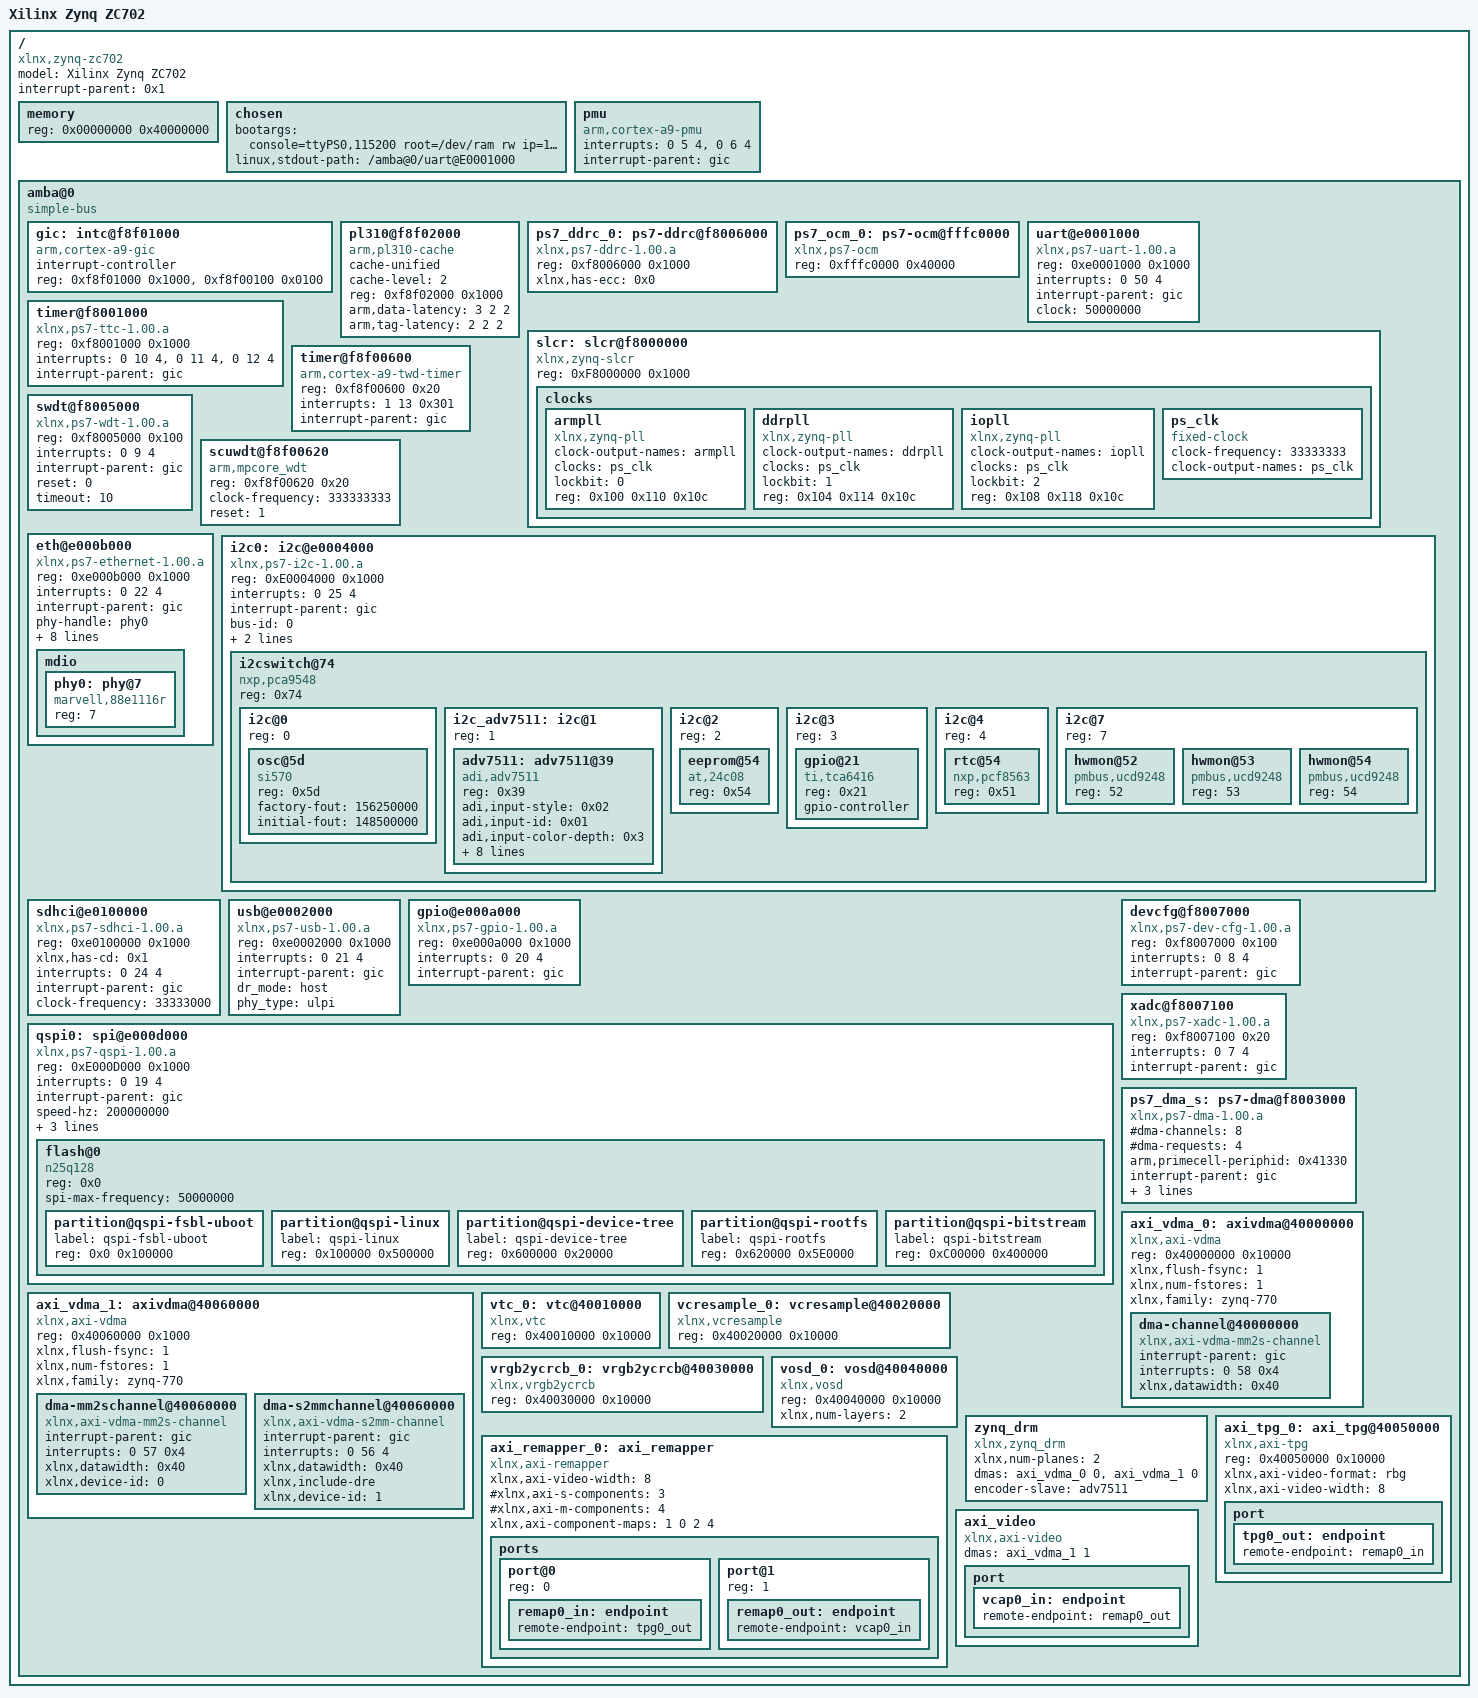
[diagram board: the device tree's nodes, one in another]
/dts-v1/;

/ {
	model = "Xilinx Zynq ZC702";
	compatible = "xlnx,zynq-zc702";
	#address-cells = <0x1>;
	#size-cells = <0x1>;
	interrupt-parent = <0x1>;

	memory {
		device_type = "memory";
		reg = <0x00000000 0x40000000>;
	};
	chosen {
		bootargs = "console=ttyPS0,115200 root=/dev/ram rw ip=192.168.1.10:::255.255.255.0:ZC702:eth0 earlyprintk";
		linux,stdout-path = "/amba@0/uart@E0001000";
	};

	pmu {
		compatible = "arm,cortex-a9-pmu";
		interrupts = <0 5 4>, <0 6 4>;
		interrupt-parent = <&gic>;
	};

	amba@0 {
		compatible = "simple-bus";
		#address-cells = <0x1>;
		#size-cells = <0x1>;
		ranges;

		gic: intc@f8f01000 {
			interrupt-controller;
			compatible = "arm,cortex-a9-gic";
			#interrupt-cells = <3>;
			reg = <0xf8f01000 0x1000>,
			      <0xf8f00100 0x0100>;
		};

		pl310@f8f02000 {
			compatible = "arm,pl310-cache";
			cache-unified;
			cache-level = <2>;
			reg = <0xf8f02000 0x1000>;
			arm,data-latency = <3 2 2>;
			arm,tag-latency = <2 2 2>;
		};

		ps7_ddrc_0: ps7-ddrc@f8006000 {
			compatible = "xlnx,ps7-ddrc-1.00.a", "xlnx,ps7-ddrc";
			reg = <0xf8006000 0x1000>;
			xlnx,has-ecc = <0x0>;
		} ;

		ps7_ocm_0: ps7-ocm@fffc0000 {
			compatible = "xlnx,ps7-ocm";
			reg = <0xfffc0000 0x40000>; /* 256k */
		};

		uart@e0001000 {
			compatible = "xlnx,ps7-uart-1.00.a";
			reg = <0xe0001000 0x1000>;
			interrupts = <0 50 4>;
			interrupt-parent = <&gic>;
			clock = <50000000>;
		};

		slcr: slcr@f8000000 {
			compatible = "xlnx,zynq-slcr";
			reg = <0xF8000000 0x1000>;
			clocks {
				#address-cells = <1>;
				#size-cells = <0>;
				armpll: armpll {
					#clock-cells = <0>;
					clock-output-names = "armpll";
					clocks = <&ps_clk>;
					compatible = "xlnx,zynq-pll";
					lockbit = <0>;
					reg = < 0x100 0x110 0x10c >;
				} ;
				ddrpll: ddrpll {
					#clock-cells = <0>;
					clock-output-names = "ddrpll";
					clocks = <&ps_clk>;
					compatible = "xlnx,zynq-pll";
					lockbit = <1>;
					reg = < 0x104 0x114 0x10c >;
				} ;
				iopll: iopll {
					#clock-cells = <0>;
					clock-output-names = "iopll";
					clocks = <&ps_clk>;
					compatible = "xlnx,zynq-pll";
					lockbit = <2>;
					reg = < 0x108 0x118 0x10c >;
				} ;
				ps_clk: ps_clk {
					#clock-cells = <0>;
					clock-frequency = <33333333>;
					clock-output-names = "ps_clk";
					compatible = "fixed-clock";
				} ;
			} ;
		};

		timer@f8001000 {
			compatible = "xlnx,ps7-ttc-1.00.a";
			reg = <0xf8001000 0x1000>;
			interrupts = <0 10 4>,<0 11 4>,<0 12 4>;
			interrupt-parent = <&gic>;
		};

		timer@f8f00600 {
			compatible = "arm,cortex-a9-twd-timer";
			reg = <0xf8f00600 0x20>;
			interrupts = <1 13 0x301>;
			interrupt-parent = <&gic>;
		};

		swdt@f8005000 {
			device_type = "watchdog";
			compatible = "xlnx,ps7-wdt-1.00.a";
			reg = <0xf8005000 0x100>;
			interrupts = <0 9 4>;
			interrupt-parent = <&gic>;
			reset = <0>;
			timeout = <10>;
		};

		scuwdt@f8f00620 {
			device_type = "watchdog";
			compatible = "arm,mpcore_wdt";
			reg = <0xf8f00620 0x20>;
			clock-frequency = <333333333>;
			reset = <1>;
		};

		eth@e000b000 {
			compatible = "xlnx,ps7-ethernet-1.00.a";
			reg = <0xe000b000 0x1000>;
			interrupts = <0 22 4>;
			interrupt-parent = <&gic>;
			phy-handle = <&phy0>;
			phy-mode = "rgmii-id";
			xlnx,ptp-enet-clock = <111111111>;
			xlnx,slcr-div0-1000Mbps = <8>;
			xlnx,slcr-div0-100Mbps = <8>;
			xlnx,slcr-div0-10Mbps = <8>;
			xlnx,slcr-div1-1000Mbps = <1>;
			xlnx,slcr-div1-100Mbps = <5>;
			xlnx,slcr-div1-10Mbps = <50>;
			#address-cells = <0x1>;
			#size-cells = <0x0>;
			mdio {
				#address-cells = <1>;
				#size-cells = <0>;
				phy0: phy@7 {
					compatible = "marvell,88e1116r";
					device_type = "ethernet-phy";
					reg = <7>;
				};
			};
		};

		i2c0: i2c@e0004000 {
			compatible = "xlnx,ps7-i2c-1.00.a";
			reg = <0xE0004000 0x1000>;
			interrupts = <0 25 4>;
			interrupt-parent = <&gic>;
			bus-id = <0>;
			input-clk = <111111111>;
			i2c-clk = <100000>;

			#address-cells = <1>;
			#size-cells = <0>;
			i2cswitch@74 {
				compatible = "nxp,pca9548";
				#address-cells = <1>;
				#size-cells = <0>;
				reg = <0x74>;

				i2c@0 {
					#address-cells = <1>;
					#size-cells = <0>;
					reg = <0>;
					osc@5d {
						compatible = "si570";
						reg = <0x5d>;
						factory-fout = <156250000>;
						initial-fout = <148500000>;
					};
				};

				i2c_adv7511: i2c@1 {
					#size-cells = <0>;
					#address-cells = <1>;
					reg = <1>;
					adv7511: adv7511@39 {
						compatible = "adi,adv7511";
						reg = <0x39>;
						adi,input-style = <0x02>;
						adi,input-id = <0x01>;
						adi,input-color-depth = <0x3>;
						adi,sync-pulse = <0x03>;
						adi,bit-justification = <0x01>;
						adi,up-conversion = <0x00>;
						adi,timing-generation-sequence = <0x00>;
						adi,vsync-polarity = <0x02>;
						adi,hsync-polarity = <0x02>;
						adi,tdms-clock-inversion;
						adi,clock-delay = <0x03>;
					};
				};

				i2c@2 {
					#address-cells = <1>;
					#size-cells = <0>;
					reg = <2>;
					eeprom@54 {
						compatible = "at,24c08";
						reg = <0x54>;
					};
				};

				i2c@3 {
					#address-cells = <1>;
					#size-cells = <0>;
					reg = <3>;
					gpio@21 {
						compatible = "ti,tca6416";
						reg = <0x21>;
						gpio-controller;
						#gpio-cells = <2>;
					};
				};

				i2c@4 {
					#address-cells = <1>;
					#size-cells = <0>;
					reg = <4>;
					rtc@54 {
						compatible = "nxp,pcf8563";
						reg = <0x51>;
					};
				};

				i2c@7 {
					#address-cells = <1>;
					#size-cells = <0>;
					reg = <7>;
					hwmon@52 {
						compatible = "pmbus,ucd9248";
						reg = <52>;
					};
					hwmon@53 {
						compatible = "pmbus,ucd9248";
						reg = <53>;
					};
					hwmon@54 {
						compatible = "pmbus,ucd9248";
						reg = <54>;
					};
				};
			};
		};

		sdhci@e0100000 {
			compatible = "xlnx,ps7-sdhci-1.00.a";
			reg = <0xe0100000 0x1000>;
			xlnx,has-cd = <0x1>;
			interrupts = <0 24 4>;
			interrupt-parent = <&gic>;
			clock-frequency = <33333000>;
		};

		usb@e0002000 {
			compatible = "xlnx,ps7-usb-1.00.a";
			reg = <0xe0002000 0x1000>;
			interrupts = <0 21 4>;
			interrupt-parent = <&gic>;
			dr_mode = "host";
			phy_type = "ulpi";
		};

		gpio@e000a000 {
			compatible = "xlnx,ps7-gpio-1.00.a";
			reg = <0xe000a000 0x1000>;
			interrupts = <0 20 4>;
			interrupt-parent = <&gic>;
		};

		qspi0: spi@e000d000 {
			compatible = "xlnx,ps7-qspi-1.00.a";
			reg = <0xE000D000 0x1000>;
			interrupts = <0 19 4>;
			interrupt-parent = <&gic>;
			speed-hz = <200000000>;
			bus-num = <1>;
			num-chip-select = <1>;
			#address-cells = <1>;
			#size-cells = <0>;
			is-dual = <0>;
			flash@0 {
				compatible = "n25q128";
				reg = <0x0>;
				spi-max-frequency = <50000000>;
				#address-cells = <1>;
				#size-cells = <1>;
				partition@qspi-fsbl-uboot {
					label = "qspi-fsbl-uboot";
					reg = <0x0 0x100000>;
				};
				partition@qspi-linux {
					label = "qspi-linux";
					reg = <0x100000 0x500000>;
				};
				partition@qspi-device-tree {
					label = "qspi-device-tree";
					reg = <0x600000 0x20000>;
				};
				partition@qspi-rootfs {
					label = "qspi-rootfs";
					reg = <0x620000 0x5E0000>;
				};
				partition@qspi-bitstream {
					label = "qspi-bitstream";
					reg = <0xC00000 0x400000>;
				};
			};
		};

		devcfg@f8007000 {
			compatible = "xlnx,ps7-dev-cfg-1.00.a";
			reg = <0xf8007000 0x100>;
			interrupts = <0 8 4>;
			interrupt-parent = <&gic>;
		};

		xadc@f8007100 {
			compatible = "xlnx,ps7-xadc-1.00.a";
			reg = <0xf8007100 0x20>;
			interrupts = <0 7 4>;
			interrupt-parent = <&gic>;
		};

		ps7_dma_s: ps7-dma@f8003000 {
			#dma-cells = <1>;
			#dma-channels = <8>;
			#dma-requests = <4>;
			arm,primecell-periphid = <0x41330>;
			compatible = "xlnx,ps7-dma-1.00.a", "arm,primecell", "arm,pl330";
			interrupt-parent = <&gic>;
			interrupts = <0 13 4 0 14 4 0 15 4 0 16 4 0 17 4 0 40 4 0 41 4 0 42 4 0 43 4>;
			reg = <0xf8003000 0x1000>;
		};

		axi_vdma_0: axivdma@40000000 {
			compatible = "xlnx,axi-vdma";
			reg = <0x40000000 0x10000>;

			xlnx,flush-fsync = <1>;
			xlnx,num-fstores = <1>;
			xlnx,family = "zynq-770";

			#dma-cells = <1>;
			dma-channel@40000000 {
				compatible = "xlnx,axi-vdma-mm2s-channel";
				interrupt-parent = <&gic>;
				interrupts = <0 58 0x4>;
				xlnx,datawidth = <0x40>;
			};
		};

		axi_vdma_1: axivdma@40060000 {
			compatible = "xlnx,axi-vdma";
			reg = <0x40060000 0x1000>;

			xlnx,flush-fsync = <1>;
			xlnx,num-fstores = <1>;
			xlnx,family = "zynq-770";

			#dma-cells = <1>;
			dma-mm2schannel@40060000 {
				compatible = "xlnx,axi-vdma-mm2s-channel";
				interrupt-parent = <&gic>;
				interrupts = <0 57 0x4>;
				xlnx,datawidth = <0x40>;
				xlnx,device-id = <0>;
			};
			dma-s2mmchannel@40060000 {
				compatible = "xlnx,axi-vdma-s2mm-channel";
				interrupt-parent = <&gic>;
				interrupts = <0 56 4>;
				xlnx,datawidth = <0x40>;
				xlnx,include-dre;
				xlnx,device-id = <1>;
			};
		};

		vtc_0: vtc@40010000 {
			compatible = "xlnx,vtc";
			reg = <0x40010000 0x10000>;
		};

		vcresample_0: vcresample@40020000 {
			compatible = "xlnx,vcresample";
			reg = <0x40020000 0x10000>;
		};

		vrgb2ycrcb_0: vrgb2ycrcb@40030000 {
			compatible = "xlnx,vrgb2ycrcb";
			reg = <0x40030000 0x10000>;
		};

		vosd_0: vosd@40040000 {
			compatible = "xlnx,vosd";
			reg = <0x40040000 0x10000>;
			xlnx,num-layers = <2>;
		};

		zynq_drm{
			compatible = "xlnx,zynq_drm";
			xlnx,num-planes = <2>;
			dmas = <&axi_vdma_0 0
				&axi_vdma_1 0>;
			dma-names = "vdma0", "vdma1";
			encoder-slave = <&adv7511>;
		};

		axi_tpg_0: axi_tpg@40050000 {
			compatible = "xlnx,axi-tpg";
			reg = <0x40050000 0x10000>;

			xlnx,axi-video-format = "rbg";
			xlnx,axi-video-width = <8>;

			port {
				tpg0_out: endpoint {
					remote-endpoint = <&remap0_in>;
				};
			};
		};

		axi_remapper_0: axi_remapper {
			compatible = "xlnx,axi-remapper";

			xlnx,axi-video-width = <8>;

			#xlnx,axi-s-components = <3>;
			#xlnx,axi-m-components = <4>;
			xlnx,axi-component-maps = <1 0 2 4>;

			ports {
				#address-cells = <1>;
				#size-cells = <0>;

				port@0 {
					reg = <0>;
					remap0_in: endpoint {
						remote-endpoint = <&tpg0_out>;
					};
				};
				port@1 {
					reg = <1>;
					remap0_out: endpoint {
						remote-endpoint = <&vcap0_in>;
					};
				};
			};
		};

		axi_video {
			compatible = "xlnx,axi-video";
			dmas = <&axi_vdma_1 1>;
			dma-names = "vdma";

			port {
				vcap0_in: endpoint {
					remote-endpoint = <&remap0_out>;
				};
			};
		};
	};
};
